# CY8C4247LTI_M475 register map
File version: 0.1
PSoC 4200M
Registers are 32-bit, read-write, no defined reset value unless marked. A register's access mark holds for its fields unless they carry their own. Offsets are from the block's base; lines under a group give offsets from that group; [hi:lo] are bit positions; {n}, {i} and the like mark numbered series; 'fields as' and 'values as' point back to an identical list; <NAME> marks a mode.

## Memory map
0x00000000 SPI_1 — Serial Communication Block
0x00000000 gpio1 — Serial Communication Block
0x00000000 LCD — Serial Communication Block
0x00000000 ADC_1 — Sequencing SAR ADC
0x00000000 console — Serial Communication Block
0x00000000 sectimer
0x40000000 DMAC — DMAC Registers
0x400F0062 switches

## switches
Base 0x400F0062
0x00 switches_STATUS_REG 8-bit
0x20 switches_MASK_REG 8-bit
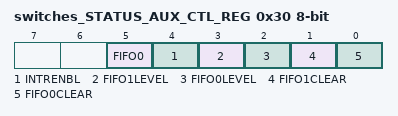
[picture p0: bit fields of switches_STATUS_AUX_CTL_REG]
0x30 switches_STATUS_AUX_CTL_REG 8-bit
  [5] FIFO0 — FIFO0 clear
    1=ENABLED (Enable counter); 0=DISABLED (Disable counter)
  [4] INTRENBL — Enables or disables the Interrupt
    1=ENABLED (Interrupt enabled); 0=DISABLED (Interrupt disabled)
  [3] FIFO1LEVEL — FIFO level
    1=ENABLED (FIFO LVL: input mode: FIFO at least 1/2 empty; output mode: FIFO at least 1/2 full); 0=DISABLED (FIFO LVL: input mode: FIFO not full; output mode: FIFO not empty)
  [2] FIFO0LEVEL — FIFO level
    values as FIFO1LEVEL
  [1] FIFO1CLEAR — FIFO clear
    1=ENABLED (Clear FIFO state); 0=DISABLED (Normal FIFO operation)
  [0] FIFO0CLEAR — FIFO clear
    values as FIFO1CLEAR

## sectimer
Base 0x00000000
0x400F0002 sectimer_COUNTER 16-bit — UDB.A0 - Current Down Counter Value
0x400F0022 sectimer_PERIOD 16-bit — UDB.D0 - Assigned Period
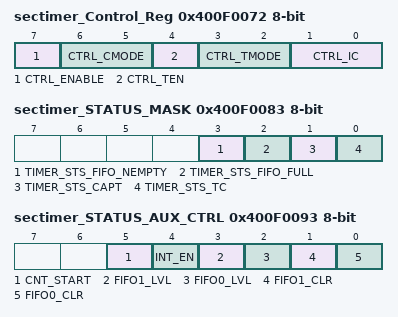
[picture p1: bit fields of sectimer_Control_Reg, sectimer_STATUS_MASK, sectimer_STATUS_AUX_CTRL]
0x400F0072 sectimer_Control_Reg 8-bit — UDB Control Register - Assigned Control Register Value
  [7] CTRL_ENABLE — Enable the Timer
  [6:5] CTRL_CMODE — Capture Mode
  [4] CTRL_TEN — Trigger Enable Bit
  [3:2] CTRL_TMODE — Trigger Mode
  [1:0] CTRL_IC — Interrupt Count
0x400F0083 sectimer_STATUS_MASK 8-bit — UDB Status bits Interrupt Mask Enable Register
  [3] TIMER_STS_FIFO_NEMPTY ro — FIFO Empty status
  [2] TIMER_STS_FIFO_FULL ro — FIFO Full Status
  [1] TIMER_STS_CAPT ro — Enables the Interrupt on Capture
  [0] TIMER_STS_TC ro — Enables the Interrupt on TC
0x400F0093 sectimer_STATUS_AUX_CTRL 8-bit — UDB Auxilliary Control Register
  [5] CNT_START — FIFO0 clear
    0=E_CNT_START0 (Disable counter); 1=E_CNT_START1 (Enable counter)
  [4] INT_EN
    0=E_INT_EN0 (Interrupt disabled); 1=E_INT_EN1 (Interrupt enabled)
  [3] FIFO1_LVL — FIFO level
    0=E_FIFO_LVL_0 (FIFO LVL: input mode: FIFO not full; output mode: FIFO not empty); 1=E_FIFO_LVL_1 (FIFO LVL: input mode: FIFO at least 1/2 empty; output mode: FIFO at least 1/2 full)
  [2] FIFO0_LVL — FIFO level
    values as FIFO1_LVL
  [1] FIFO1_CLR — FIFO1 clear
    0=E_FIFO_CLR_0 (Normal FIFO operation); 1=E_FIFO_CLR_1 (Clear FIFO state)
  [0] FIFO0_CLR — FIFO0 clear
    values as FIFO1_CLR
